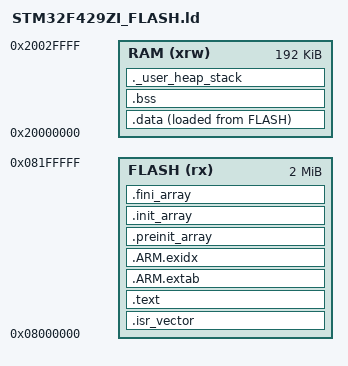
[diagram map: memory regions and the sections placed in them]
/* STM32F429ZI: 2 MiB Flash, 192 KiB SRAM. CCM is not allocated. ST GCC startup symbols. */
ENTRY(Reset_Handler)
MEMORY
{
  FLASH (rx)  : ORIGIN = 0x08000000, LENGTH = 2048K
  RAM (xrw)  : ORIGIN = 0x20000000, LENGTH = 192K
}
_estack = ORIGIN(RAM) + LENGTH(RAM);
_Min_Heap_Size = 0x200;
_Min_Stack_Size = 0x800;
SECTIONS
{
  .isr_vector : { . = ALIGN(4); KEEP(*(.isr_vector)) . = ALIGN(4); } >FLASH
  .text : {
    . = ALIGN(4);
    *(.text .text.*) *(.rodata .rodata.*)
    KEEP(*(.init)) KEEP(*(.fini))
    . = ALIGN(4);
    _etext = .;
  } >FLASH
  .ARM.extab : { *(.ARM.extab* .gnu.linkonce.armextab.*) } >FLASH
  .ARM.exidx : {
    __exidx_start = .; *(.ARM.exidx*) __exidx_end = .;
  } >FLASH
  .preinit_array : {
    PROVIDE_HIDDEN(__preinit_array_start = .);
    KEEP(*(.preinit_array*))
    PROVIDE_HIDDEN(__preinit_array_end = .);
  } >FLASH
  .init_array : {
    PROVIDE_HIDDEN(__init_array_start = .);
    KEEP(*(SORT(.init_array.*))) KEEP(*(.init_array*))
    PROVIDE_HIDDEN(__init_array_end = .);
  } >FLASH
  .fini_array : {
    PROVIDE_HIDDEN(__fini_array_start = .);
    KEEP(*(SORT(.fini_array.*))) KEEP(*(.fini_array*))
    PROVIDE_HIDDEN(__fini_array_end = .);
  } >FLASH
  _sidata = LOADADDR(.data);
  .data : {
    . = ALIGN(4); _sdata = .;
    *(.data .data.*) . = ALIGN(4); _edata = .;
  } >RAM AT> FLASH
  .bss (NOLOAD) : {
    . = ALIGN(4); _sbss = .; __bss_start__ = .;
    *(.bss .bss.*) *(COMMON)
    . = ALIGN(4); _ebss = .; __bss_end__ = .;
  } >RAM
  ._user_heap_stack (NOLOAD) : {
    . = ALIGN(8); PROVIDE(end = .); PROVIDE(_end = .);
    . += _Min_Heap_Size; . += _Min_Stack_Size; . = ALIGN(8);
  } >RAM
  .ARM.attributes 0 : { *(.ARM.attributes) }
}
ASSERT(_estack % 8 == 0, "Stack must be 8-byte aligned")
ASSERT(SIZEOF(._user_heap_stack) + ADDR(._user_heap_stack) <= _estack,
       "RAM data, heap and stack exceed 192 KiB")
